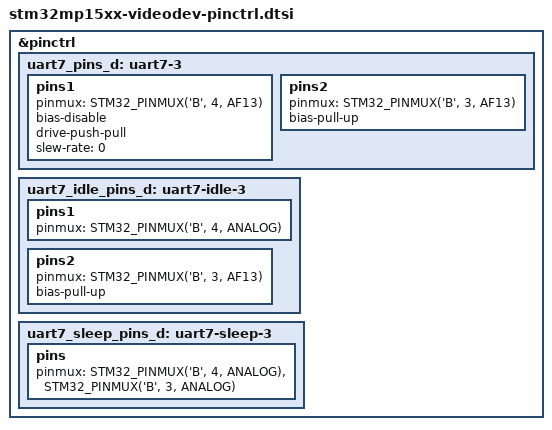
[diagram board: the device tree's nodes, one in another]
#include <dt-bindings/pinctrl/stm32-pinfunc.h>

&pinctrl {
	uart7_pins_d: uart7-3 {
		pins1 {
			pinmux = <STM32_PINMUX('B', 4, AF13)>; /* UART7_TX */
			bias-disable;
			drive-push-pull;
			slew-rate = <0>;
		};
		pins2 {
			pinmux = <STM32_PINMUX('B', 3, AF13)>; /* UART7_RX */
			bias-pull-up;
		};
	};

	uart7_idle_pins_d: uart7-idle-3 {
		pins1 {
			pinmux = <STM32_PINMUX('B', 4, ANALOG)>; /* UART7_TX */
		};
		pins2 {
			pinmux = <STM32_PINMUX('B', 3, AF13)>; /* UART7_RX */
			bias-pull-up;
		};
	};

	uart7_sleep_pins_d: uart7-sleep-3 {
		pins {
			pinmux = <STM32_PINMUX('B', 4, ANALOG)>, /* UART7_TX */
				 <STM32_PINMUX('B', 3, ANALOG)>; /* UART7_RX */
		};
	};

};

